AUTOSAR XML (schema 314)
package /ComponentType
  internal behavior Sa_HwTrq_InternalBehavior: component=Sa_HwTrq
    4 x timing event:
      HwTrq_InitEvent: start-on-event=HwTrq_Init, period=0
      TMT_HwTrq_Per1: start-on-event=HwTrq_Per1, period=0.002
      TMT_HwTrq_Per2: start-on-event=HwTrq_Per2, period=0.004
      TMT_HwTrq_Per3: start-on-event=HwTrq_Per3, period=0.1
    9 x operation invoked event:
      OIT_HwTrq_SCom_ClrHwTrqScale_HwTrq_SCom_ClrHwTrqScale: start-on-event=HwTrq_SCom_ClrHwTrqScale, operation=HwTrq_SCom.ClrHwTrqScale
      OIT_HwTrq_SCom_ClrHwTrqTrim_HwTrq_SCom_ClrHwTrqTrim: start-on-event=HwTrq_SCom_ClrHwTrqTrim, operation=HwTrq_SCom.ClrHwTrqTrim
      OIT_HwTrq_SCom_ManualSetHwTrqTrim_HwTrq_SCom_ManualSetHwTrqTrim: start-on-event=HwTrq_SCom_ManualSetHwTrqTrim, operation=HwTrq_SCom.ManualSetHwTrqTrim
      OIT_HwTrq_SCom_ReadEOLTrqStep_HwTrq_SCom_ReadEOLTrqStep: start-on-event=HwTrq_SCom_ReadEOLTrqStep, operation=HwTrq_SCom.ReadEOLTrqStep
      OIT_HwTrq_SCom_ReadHwTrqScale_HwTrq_SCom_ReadHwTrqScale: start-on-event=HwTrq_SCom_ReadHwTrqScale, operation=HwTrq_SCom.ReadHwTrqScale
      OIT_HwTrq_SCom_ReadHwTrqTrim_HwTrq_SCom_ReadHwTrqTrim: start-on-event=HwTrq_SCom_ReadHwTrqTrim, operation=HwTrq_SCom.ReadHwTrqTrim
      OIT_HwTrq_SCom_SetEOLTrqStep_HwTrq_SCom_SetEOLTrqStep: start-on-event=HwTrq_SCom_SetEOLTrqStep, operation=HwTrq_SCom.SetEOLTrqStep
      OIT_HwTrq_SCom_SetHwTrqScale_HwTrq_SCom_SetHwTrqScale: start-on-event=HwTrq_SCom_SetHwTrqScale, operation=HwTrq_SCom.SetHwTrqScale
      OIT_HwTrq_SCom_SetHwTrqTrim_HwTrq_SCom_SetHwTrqTrim: start-on-event=HwTrq_SCom_SetHwTrqTrim, operation=HwTrq_SCom.SetHwTrqTrim
    per instance memory EOLTrqStepData: type=EOLTrqStepType, type-definition=/DataType/EOLTrqStepType
    per instance memory HwTrqScaleData: type=HwTrqScale_Datatype, type-definition=/DataType/HwTrqScale_Datatype
    per instance memory HwTrqTrimData: type=HwTrqTrim_Datatype, type-definition=/DataType/HwTrqTrim_Datatype
    port-api-options:
      enable-take-address=false, indirect-api=false, port=AbsPosStepSignal
      enable-take-address=false, indirect-api=false, port=AnaDiffHwTrq
      enable-take-address=false, indirect-api=false, port=AnaHwTorque
      enable-take-address=false, indirect-api=false, port=CntrlDisRampComplete
      enable-take-address=false, indirect-api=false, port=EOLTrqStep
      enable-take-address=false, indirect-api=false, port=ErrorActiveAnalog
      enable-take-address=false, indirect-api=false, port=HwTrq_Per3_CP0
      enable-take-address=false, indirect-api=false, port=HwTrq_SCom
      enable-take-address=false, indirect-api=false, port=HwTrqScale
      enable-take-address=false, indirect-api=false, port=HwTrqScaleVal
      enable-take-address=false, indirect-api=false, port=HwTrqTrim
      enable-take-address=false, indirect-api=false, port=MECCounter
      enable-take-address=false, indirect-api=false, port=NxtrDiagMgr
      enable-take-address=false, indirect-api=false, port=SrlComHwTrqValid
      enable-take-address=false, indirect-api=false, port=SysCAnaHwTorque
      enable-take-address=false, indirect-api=false, port=SysCHwTorqueSqd
      enable-take-address=false, indirect-api=false, port=T1ADC
      enable-take-address=false, indirect-api=false, port=T1TrimVal
      enable-take-address=false, indirect-api=false, port=T2ADC
      enable-take-address=false, indirect-api=false, port=T2TrimVal
    13 x runnable:
      HwTrq_Init
        data read access READ_MECCounter_Cnt_enum: data-element=MECCounter.Cnt_enum
        data write access WRITE_HwTrqScaleVal_VoltsPerDeg_f32: data-element=HwTrqScaleVal.VoltsPerDeg_f32
        data write access WRITE_T1TrimVal_Volt_f32: data-element=T1TrimVal.Volt_f32
        data write access WRITE_T2TrimVal_Volt_f32: data-element=T2TrimVal.Volt_f32
        sync call SC_HwTrqTrim_GetErrorStatus: operation=HwTrqTrim.GetErrorStatus, timeout=0
        sync call SC_NxtrDiagMgr_SetNTCStatus: operation=NxtrDiagMgr.SetNTCStatus, timeout=0
      HwTrq_Per1
        data read access READ_AbsPosStepSignal_Cnt_u08: data-element=AbsPosStepSignal.Cnt_u08
        data read access READ_T1ADC_Volt_f32: data-element=T1ADC.Volt_f32
        data read access READ_T2ADC_Volt_f32: data-element=T2ADC.Volt_f32
        5 x data write access:
          WRITE_AnaDiffHwTrq_Volt_f32: data-element=AnaDiffHwTrq.Volt_f32
          WRITE_AnaHwTorque_HwNm_f32: data-element=AnaHwTorque.HwNm_f32
          WRITE_ErrorActiveAnalog_Cnt_enum: data-element=ErrorActiveAnalog.Cnt_enum
          WRITE_SrlComHwTrqValid_Cnt_lgc: data-element=SrlComHwTrqValid.Cnt_lgc
          WRITE_SysCAnaHwTorque_HwNm_f32: data-element=SysCAnaHwTorque.HwNm_f32
        sync call SC_NxtrDiagMgr_GetNTCStatus: operation=NxtrDiagMgr.GetNTCStatus, timeout=0
        sync call SC_NxtrDiagMgr_SetNTCStatus: operation=NxtrDiagMgr.SetNTCStatus, timeout=0
      HwTrq_Per2
        4 x data read access:
          READ_CntrlDisRampComplete_Cnt_lgc: data-element=CntrlDisRampComplete.Cnt_lgc
          READ_SysCHwTorqueSqd_HwNmSq_f32: data-element=SysCHwTorqueSqd.HwNmSq_f32
          READ_T1ADC_Volt_f32: data-element=T1ADC.Volt_f32
          READ_T2ADC_Volt_f32: data-element=T2ADC.Volt_f32
        sync call SC_NxtrDiagMgr_GetNTCFailed: operation=NxtrDiagMgr.GetNTCFailed, timeout=0
        sync call SC_NxtrDiagMgr_GetNTCStatus: operation=NxtrDiagMgr.GetNTCStatus, timeout=0
        sync call SC_NxtrDiagMgr_SetNTCStatus: operation=NxtrDiagMgr.SetNTCStatus, timeout=0
      HwTrq_Per3
        sync call SC_HwTrq_Per3_CP0_CheckpointReached: operation=HwTrq_Per3_CP0.CheckpointReached, timeout=0
      HwTrq_SCom_ClrHwTrqScale
        data receive point REC_MECCounter_Cnt_enum: data-element=MECCounter.Cnt_enum
        data send point SEND_HwTrqScaleVal_VoltsPerDeg_f32: data-element=HwTrqScaleVal.VoltsPerDeg_f32
        sync call SC_HwTrqScale_WriteBlock: operation=HwTrqScale.WriteBlock, timeout=0
      HwTrq_SCom_ClrHwTrqTrim
        data receive point REC_MECCounter_Cnt_enum: data-element=MECCounter.Cnt_enum
        data send point SEND_T1TrimVal_Volt_f32: data-element=T1TrimVal.Volt_f32
        data send point SEND_T2TrimVal_Volt_f32: data-element=T2TrimVal.Volt_f32
        sync call SC_HwTrqTrim_WriteBlock: operation=HwTrqTrim.WriteBlock, timeout=0
      HwTrq_SCom_ManualSetHwTrqTrim
        data receive point REC_MECCounter_Cnt_enum: data-element=MECCounter.Cnt_enum
        data send point SEND_T1TrimVal_Volt_f32: data-element=T1TrimVal.Volt_f32
        data send point SEND_T2TrimVal_Volt_f32: data-element=T2TrimVal.Volt_f32
        sync call SC_HwTrqTrim_WriteBlock: operation=HwTrqTrim.WriteBlock, timeout=0
      HwTrq_SCom_ReadEOLTrqStep
      HwTrq_SCom_ReadHwTrqScale
      HwTrq_SCom_ReadHwTrqTrim
      HwTrq_SCom_SetEOLTrqStep
        sync call SC_EOLTrqStep_WriteBlock: operation=EOLTrqStep.WriteBlock, timeout=0
      HwTrq_SCom_SetHwTrqScale
        data receive point REC_MECCounter_Cnt_enum: data-element=MECCounter.Cnt_enum
        data send point SEND_HwTrqScaleVal_VoltsPerDeg_f32: data-element=HwTrqScaleVal.VoltsPerDeg_f32
        sync call SC_HwTrqScale_WriteBlock: operation=HwTrqScale.WriteBlock, timeout=0
      HwTrq_SCom_SetHwTrqTrim
        data receive point REC_MECCounter_Cnt_enum: data-element=MECCounter.Cnt_enum
        data receive point REC_T1ADC_Volt_f32: data-element=T1ADC.Volt_f32
        data receive point REC_T2ADC_Volt_f32: data-element=T2ADC.Volt_f32
        data send point SEND_T1TrimVal_Volt_f32: data-element=T1TrimVal.Volt_f32
        data send point SEND_T2TrimVal_Volt_f32: data-element=T2TrimVal.Volt_f32
        sync call SC_HwTrqTrim_WriteBlock: operation=HwTrqTrim.WriteBlock, timeout=0
    service-needss:
      swc nv block needs HwTrqTrim_EOLData: n-data-sets=0, readonly=false, reliability=LOW, resistant-to-changed-sw=false, restore-at-start=false, write-only-once=false, writing-frequency=0, writing-priority=LOW, mirror-block=HwTrqTrimData
      swc nv block needs HwTrqScaleBlk: n-data-sets=0, readonly=false, reliability=LOW, resistant-to-changed-sw=false, restore-at-start=false, write-only-once=false, writing-frequency=0, writing-priority=LOW, mirror-block=HwTrqScaleData
      swc nv block needs HwTrqEOLTrqStepBlk: n-data-sets=0, readonly=false, reliability=LOW, resistant-to-changed-sw=false, restore-at-start=false, write-only-once=false, writing-frequency=0, writing-priority=LOW, mirror-block=EOLTrqStepData
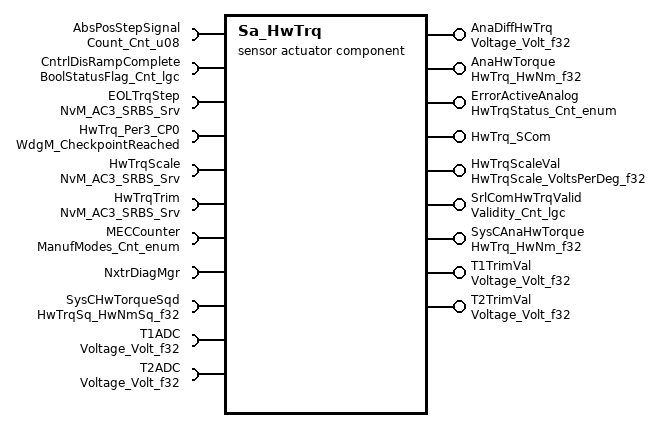
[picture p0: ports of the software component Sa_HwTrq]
  sensor actuator software component type Sa_HwTrq
    9 x provide port:
      AnaDiffHwTrq: unqueued-sender-com-spec{data-element=Volt_f32, can-invalidate=false, init-value=D_ZERO_ULS_F32}, provided-interface=Voltage_Volt_f32
      AnaHwTorque: unqueued-sender-com-spec{data-element=HwNm_f32, can-invalidate=false, init-value=D_ZERO_ULS_F32}, provided-interface=HwTrq_HwNm_f32
      ErrorActiveAnalog: unqueued-sender-com-spec{data-element=Cnt_enum, can-invalidate=false, init-value=D_HWTRQSTATUSINIT_CNT_ENUM}, provided-interface=HwTrqStatus_Cnt_enum
      HwTrq_SCom: provided-interface=HwTrq_SCom
        provided-com-specs:
          operation=ClrHwTrqScale, queue-length=1
          operation=ClrHwTrqTrim, queue-length=1
          operation=ManualSetHwTrqTrim, queue-length=1
          operation=ReadEOLTrqStep, queue-length=1
          operation=ReadHwTrqScale, queue-length=1
          operation=ReadHwTrqTrim, queue-length=1
          operation=SetEOLTrqStep, queue-length=1
          operation=SetHwTrqScale, queue-length=1
          operation=SetHwTrqTrim, queue-length=1
      HwTrqScaleVal: unqueued-sender-com-spec{data-element=VoltsPerDeg_f32, can-invalidate=false, init-value=D_ZERO_ULS_F32}, provided-interface=HwTrqScale_VoltsPerDeg_f32
      SrlComHwTrqValid: unqueued-sender-com-spec{data-element=Cnt_lgc, can-invalidate=false, init-value=D_FALSE_CNT_LGC}, provided-interface=Validity_Cnt_lgc
      SysCAnaHwTorque: unqueued-sender-com-spec{data-element=HwNm_f32, can-invalidate=false, init-value=D_ZERO_ULS_F32}, provided-interface=HwTrq_HwNm_f32
      T1TrimVal: unqueued-sender-com-spec{data-element=Volt_f32, can-invalidate=false, init-value=D_ZERO_ULS_F32}, provided-interface=Voltage_Volt_f32
      T2TrimVal: unqueued-sender-com-spec{data-element=Volt_f32, can-invalidate=false, init-value=D_ZERO_ULS_F32}, provided-interface=Voltage_Volt_f32
    11 x require port:
      AbsPosStepSignal: unqueued-receiver-com-spec{data-element=Cnt_u08, init-value=D_ZERO_CNT_U8}, required-interface=Count_Cnt_u08
      CntrlDisRampComplete: unqueued-receiver-com-spec{data-element=Cnt_lgc, init-value=D_FALSE_CNT_LGC}, required-interface=BoolStatusFlag_Cnt_lgc
      EOLTrqStep: required-com-specs=[EraseBlock, GetErrorStatus, InvalidateNvBlock, ReadBlock, SetRamBlockStatus, WriteBlock], required-interface=NvM_AC3_SRBS_Srv
      HwTrq_Per3_CP0: client-com-spec=CheckpointReached, required-interface=WdgM_CheckpointReached
      HwTrqScale: required-com-specs=[EraseBlock, GetErrorStatus, InvalidateNvBlock, ReadBlock, SetRamBlockStatus, WriteBlock], required-interface=NvM_AC3_SRBS_Srv
      HwTrqTrim: required-com-specs=[EraseBlock, GetErrorStatus, InvalidateNvBlock, ReadBlock, SetRamBlockStatus, WriteBlock], required-interface=NvM_AC3_SRBS_Srv
      MECCounter: unqueued-receiver-com-spec{data-element=Cnt_enum, init-value=D_MANUFMODEINIT_CNT_ENUM}, required-interface=ManufModes_Cnt_enum
      NxtrDiagMgr: required-com-specs=[GetNTCActive, GetNTCFailed, GetNTCStatus, SetNTCStatus], required-interface=NxtrDiagMgr
      SysCHwTorqueSqd: unqueued-receiver-com-spec{data-element=HwNmSq_f32, init-value=D_ZERO_ULS_F32}, required-interface=HwTrqSq_HwNmSq_f32
      T1ADC: unqueued-receiver-com-spec{data-element=Volt_f32, init-value=D_ZERO_ULS_F32}, required-interface=Voltage_Volt_f32
      T2ADC: unqueued-receiver-com-spec{data-element=Volt_f32, init-value=D_ZERO_ULS_F32}, required-interface=Voltage_Volt_f32
  swc implementation Sa_HwTrq_Implementation: behavior=Sa_HwTrq_InternalBehavior
    code-descriptors:
      code Code: type=SRC
